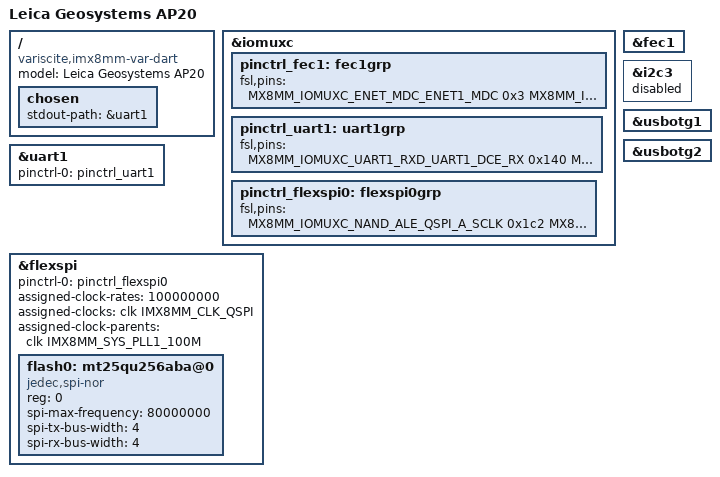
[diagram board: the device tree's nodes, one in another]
/*
 * Copyright 2018 NXP
 * Copyright 2018-2020 Variscite Ltd.
 * Copyright 2021 Leica Geosystems AG
 *
 * This program is free software; you can redistribute it and/or
 * modify it under the terms of the GNU General Public License
 * as published by the Free Software Foundation; either version 2
 * of the License, or (at your option) any later version.
 *
 * This program is distributed in the hope that it will be useful,
 * but WITHOUT ANY WARRANTY; without even the implied warranty of
 * MERCHANTABILITY or FITNESS FOR A PARTICULAR PURPOSE.  See the
 * GNU General Public License for more details.
 */

/dts-v1/;

#include "imx8mm-var-dart.dtsi"

/ {
	model = "Leica Geosystems AP20";
	compatible = "variscite,imx8mm-var-dart", "fsl,imx8mm";

	chosen {
		stdout-path = &uart1;
	};
	
	/delete-node/ reg_eth_phy;
};

&iomuxc {
	/delete-node/ pinctrl_reg_fec1;
	/delete-node/ pinctrl_i2c3;
	/delete-node/ pinctrl_i2c3_gpio;
	
	pinctrl_fec1: fec1grp {
		fsl,pins = <
			MX8MM_IOMUXC_ENET_MDC_ENET1_MDC			0x3
			MX8MM_IOMUXC_ENET_MDIO_ENET1_MDIO		0x3
			MX8MM_IOMUXC_ENET_TD3_ENET1_RGMII_TD3		0x1f
			MX8MM_IOMUXC_ENET_TD2_ENET1_RGMII_TD2		0x1f
			MX8MM_IOMUXC_ENET_TD1_ENET1_RGMII_TD1		0x1f
			MX8MM_IOMUXC_ENET_TD0_ENET1_RGMII_TD0		0x1f
			MX8MM_IOMUXC_ENET_RD3_ENET1_RGMII_RD3		0x91
			MX8MM_IOMUXC_ENET_RD2_ENET1_RGMII_RD2		0x91
			MX8MM_IOMUXC_ENET_RD1_ENET1_RGMII_RD1		0x91
			MX8MM_IOMUXC_ENET_RD0_ENET1_RGMII_RD0		0x91
			MX8MM_IOMUXC_ENET_TXC_ENET1_RGMII_TXC		0x1f
			MX8MM_IOMUXC_ENET_RXC_ENET1_RGMII_RXC		0x91
			MX8MM_IOMUXC_ENET_RX_CTL_ENET1_RGMII_RX_CTL	0x91
			MX8MM_IOMUXC_ENET_TX_CTL_ENET1_RGMII_TX_CTL	0x1f
		>;
	};

	pinctrl_uart1: uart1grp {
		fsl,pins = <
			MX8MM_IOMUXC_UART1_RXD_UART1_DCE_RX		0x140
			MX8MM_IOMUXC_UART1_TXD_UART1_DCE_TX		0x140
		>;
	};

	pinctrl_flexspi0: flexspi0grp {
		fsl,pins = <
			MX8MM_IOMUXC_NAND_ALE_QSPI_A_SCLK               0x1c2
			MX8MM_IOMUXC_NAND_CE0_B_QSPI_A_SS0_B            0x82
			MX8MM_IOMUXC_NAND_DATA00_QSPI_A_DATA0           0x82
			MX8MM_IOMUXC_NAND_DATA01_QSPI_A_DATA1           0x82
			MX8MM_IOMUXC_NAND_DATA02_QSPI_A_DATA2           0x82
			MX8MM_IOMUXC_NAND_DATA03_QSPI_A_DATA3           0x82
		>;
	};
};

&uart1 { /* console */
	pinctrl-names = "default";
	pinctrl-0 = <&pinctrl_uart1>;
	status = "okay";
};

&fec1 {
	/delete-property/ phy-reset-gpios;
};

&flexspi {
	pinctrl-names = "default";
	pinctrl-0 = <&pinctrl_flexspi0>;
	status = "okay";
	assigned-clock-rates = <100000000>;
	assigned-clocks = <&clk IMX8MM_CLK_QSPI>;
	assigned-clock-parents = <&clk IMX8MM_SYS_PLL1_100M>;

	flash0: mt25qu256aba@0 {
		reg = <0>;
		#address-cells = <1>;
		#size-cells = <1>;
		compatible = "jedec,spi-nor";
		spi-max-frequency = <80000000>;
		spi-tx-bus-width = <4>;
		spi-rx-bus-width = <4>;
	};
};

&i2c3 {
	status = "disabled";
};

&usbotg1 {
	status = "okay";
};

&usbotg2 {
	status = "okay";
};
